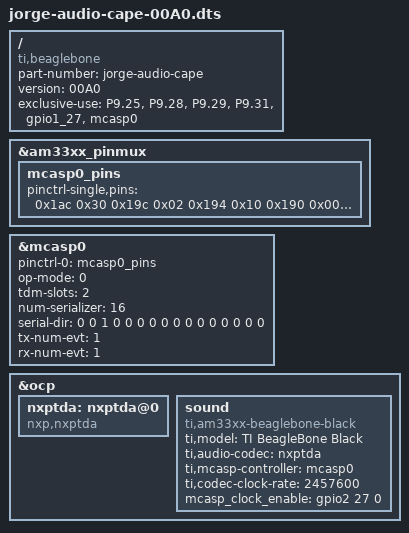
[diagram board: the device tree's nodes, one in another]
/* Copyright (C) 2012 Texas Instruments Incorporated - http://www.ti.com/
*
* This program is free software; you can redistribute it and/or modify
* it under the terms of the GNU General Purpose License Version 2 as
* published by the Free Software Foundation
*
* Original from: github.com/jadonk/validation-scripts/blob/master/test-capemgr/ 
*
* Modified by Jorge Garcia for the purposes of running my audio cape. This one disables using 9.27 as the clock
*/

/dts-v1/;
/plugin/;

/{
    compatible = "ti,beaglebone", "ti,beaglebone-black";
    part-number = "jorge-audio-cape";
    version = "00A0";
	
	/* state the resources this cape uses */
	exclusive-use =
		/* the pin header uses */
		"P9.25",	/* mcasp0: mcasp0_ahclkx */
		"P9.28",	/* mcasp0: mcasp0_axr2 */
		"P9.29",	/* mcasp0: mcasp0_fsx */
		"P9.31",	/* mcasp0: mcasp0_aclkx */
		"gpio1_27",
		"mcasp0";
	
	fragment@0 {
	target = <&am33xx_pinmux>;
		__overlay__ {
			mcasp0_pins: mcasp0_pins {
				pinctrl-single,pins = <
					0x1ac 0x30      /* mcasp0_ahclkx,       MODE0 | INPUT */
					0x19c 0x02	/* mcasp0_ahclkr, */
					0x194 0x10      /* mcasp0_fsx,         MODE0 | OUTPUT  */
					0x190 0x00      /* mcasp0_aclkr.mcasp0_aclkx,     MODE0 | OUTPUT_PULLDOWN */
					0x06c 0x07  /* gpmc_a11 GPIO1_27   MODE7 | OUTPUT | PULLDOWN not necessary for my application*/
				>;
			};
		};
	};
	
	fragment@1 {
		target = <&mcasp0>;
		__overlay__ {
			pinctrl-names = "default";
			pinctrl-0 = <&mcasp0_pins>;

			status = "okay";

			op-mode = <0>;          /* MCASP_IIS_MODE */
			tdm-slots = <2>;
			num-serializer = <16>;
			serial-dir = <  /* 0: INACTIVE, 1: TX, 2: RX */
				0 0 1 0
				0 0 0 0
				0 0 0 0
				0 0 0 0
			>;
			tx-num-evt = <1>;
			rx-num-evt = <1>;
		};
	};

	fragment@2 {
		target = <&ocp>;
		__overlay__ {
			
			/* avoid stupid warning */
			#address-cells = <1>;
			#size-cells = <1>;

			nxptda: nxptda@0 {
			       compatible = "nxp,nxptda";
			       status = "okay";
			};
			
			sound {
				compatible = "ti,am33xx-beaglebone-black";
				ti,model = "TI BeagleBone Black";
				ti,audio-codec = <&nxptda>;
				ti,mcasp-controller = <&mcasp0>;
				ti,codec-clock-rate = <2457600>;
				mcasp_clock_enable = <&gpio2 27 0>; /* BeagleBone Black Clk enable on GPIO1_27, not necessary for my shield */
			};
		};
	};
};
